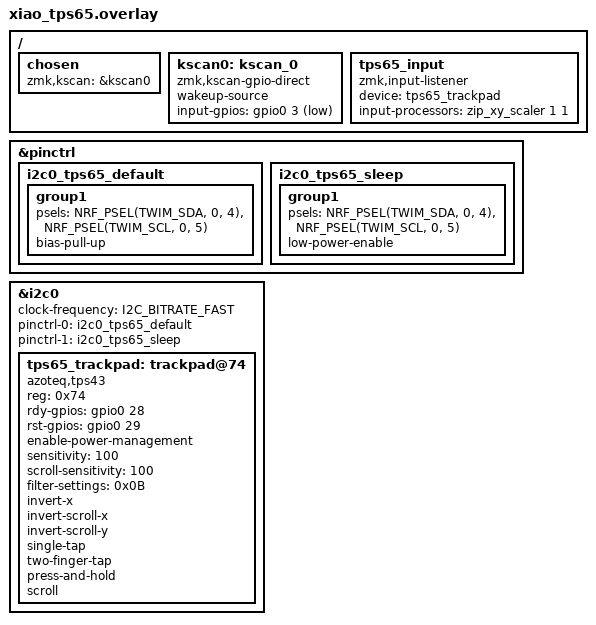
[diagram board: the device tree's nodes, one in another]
#include <dt-bindings/zmk/matrix_transform.h>
#include <dt-bindings/zmk/input_transform.h>
#include <input/processors.dtsi>

/*
 * Seeed Studio XIAO nRF52840 (Plus) <-> Azoteq TPS65 (IQS550) wiring
 *
 *   XIAO pad      nRF52840   TPS65 pin
 *   -----------   --------   --------------------
 *   3V3           -          VDD  (3.3V)
 *   GND           -          GND
 *   D4 (SDA)      P0.04      SDA
 *   D5 (SCL)      P0.05      SCL
 *   D2            P0.28      RDY / DR  (data ready)
 *   D3            P0.29      NRST      (reset)
 *   D1            P0.03      optional push button to GND (right click)
 *
 * The Plus variant exposes extra pads on the back of the board; the standard
 * D0-D10 castellated pads used here are identical on XIAO nRF52840 and Plus.
 */

/ {
    chosen {
        zmk,kscan = &kscan0;
    };

    kscan0: kscan_0 {
        compatible = "zmk,kscan-gpio-direct";
        wakeup-source;
        input-gpios = <&gpio0 3 (GPIO_ACTIVE_LOW | GPIO_PULL_UP)>;
    };
};

&pinctrl {
    i2c0_tps65_default: i2c0_tps65_default {
        group1 {
            psels = <NRF_PSEL(TWIM_SDA, 0, 4)>,
                    <NRF_PSEL(TWIM_SCL, 0, 5)>;
            bias-pull-up;
        };
    };

    i2c0_tps65_sleep: i2c0_tps65_sleep {
        group1 {
            psels = <NRF_PSEL(TWIM_SDA, 0, 4)>,
                    <NRF_PSEL(TWIM_SCL, 0, 5)>;
            low-power-enable;
        };
    };
};

&i2c0 {
    status = "okay";
    clock-frequency = <I2C_BITRATE_FAST>;
    pinctrl-0 = <&i2c0_tps65_default>;
    pinctrl-1 = <&i2c0_tps65_sleep>;
    pinctrl-names = "default", "sleep";

    tps65_trackpad: trackpad@74 {
        compatible = "azoteq,tps43"; /* same IQS5xx driver covers TPS43 and TPS65 */
        reg = <0x74>;
        status = "okay";

        rdy-gpios = <&gpio0 28 GPIO_ACTIVE_HIGH>;
        rst-gpios = <&gpio0 29 GPIO_ACTIVE_HIGH>;

        enable-power-management;

        sensitivity = <100>;
        scroll-sensitivity = <100>;
        filter-settings = <0x0B>;

        /* Adjust to match your TPS65 module orientation / panel */
        // switch-xy;
        invert-x;
        // invert-y;
        invert-scroll-x;
        invert-scroll-y;

        single-tap;
        two-finger-tap;
        press-and-hold;
        scroll;
    };
};

/ {
    tps65_input: tps65_input {
        compatible = "zmk,input-listener";
        device = <&tps65_trackpad>;
        input-processors = <&zip_xy_scaler 1 1>;
    };
};
